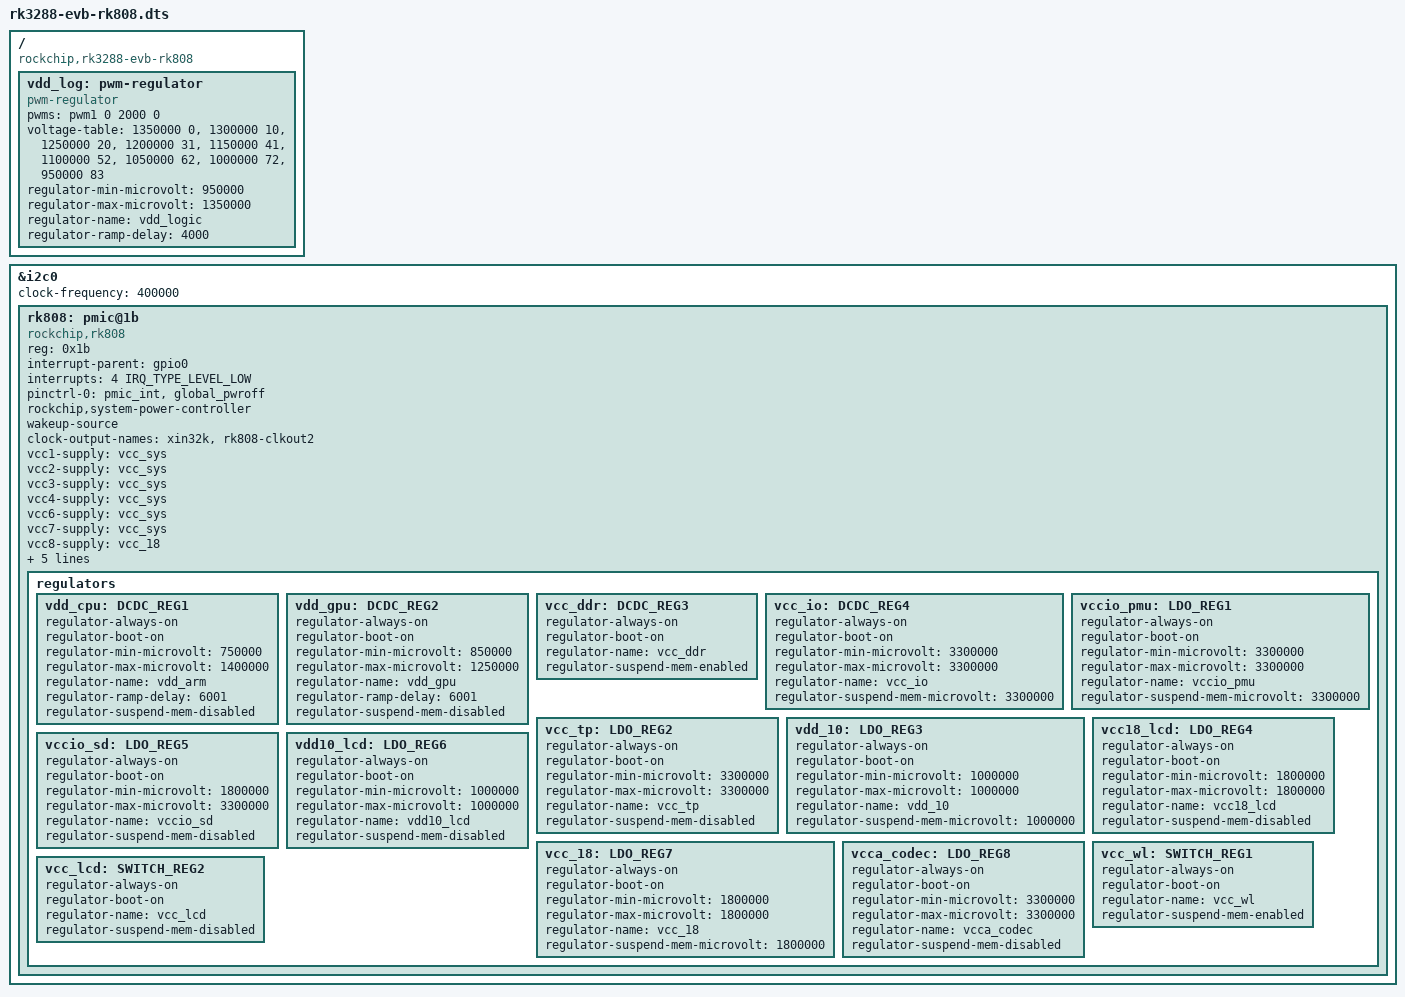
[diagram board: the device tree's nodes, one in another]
/*
 * This file is dual-licensed: you can use it either under the terms
 * of the GPL or the X11 license, at your option. Note that this dual
 * licensing only applies to this file, and not this project as a
 * whole.
 *
 *  a) This file is free software; you can redistribute it and/or
 *     modify it under the terms of the GNU General Public License as
 *     published by the Free Software Foundation; either version 2 of the
 *     License, or (at your option) any later version.
 *
 *     This file is distributed in the hope that it will be useful,
 *     but WITHOUT ANY WARRANTY; without even the implied warranty of
 *     MERCHANTABILITY or FITNESS FOR A PARTICULAR PURPOSE.  See the
 *     GNU General Public License for more details.
 *
 * Or, alternatively,
 *
 *  b) Permission is hereby granted, free of charge, to any person
 *     obtaining a copy of this software and associated documentation
 *     files (the "Software"), to deal in the Software without
 *     restriction, including without limitation the rights to use,
 *     copy, modify, merge, publish, distribute, sublicense, and/or
 *     sell copies of the Software, and to permit persons to whom the
 *     Software is furnished to do so, subject to the following
 *     conditions:
 *
 *     The above copyright notice and this permission notice shall be
 *     included in all copies or substantial portions of the Software.
 *
 *     THE SOFTWARE IS PROVIDED "AS IS", WITHOUT WARRANTY OF ANY KIND,
 *     EXPRESS OR IMPLIED, INCLUDING BUT NOT LIMITED TO THE WARRANTIES
 *     OF MERCHANTABILITY, FITNESS FOR A PARTICULAR PURPOSE AND
 *     NONINFRINGEMENT. IN NO EVENT SHALL THE AUTHORS OR COPYRIGHT
 *     HOLDERS BE LIABLE FOR ANY CLAIM, DAMAGES OR OTHER LIABILITY,
 *     WHETHER IN AN ACTION OF CONTRACT, TORT OR OTHERWISE, ARISING
 *     FROM, OUT OF OR IN CONNECTION WITH THE SOFTWARE OR THE USE OR
 *     OTHER DEALINGS IN THE SOFTWARE.
 */

/dts-v1/;
#include "rk3288-evb.dtsi"

/ {
	compatible = "rockchip,rk3288-evb-rk808", "google,veyron-jerry-rev0",
		     "rockchip,rk3288";

	vdd_log: pwm-regulator {
		compatible = "pwm-regulator";
		pwms = <&pwm1 0 2000 0>;

		voltage-table = <1350000 0>,
				<1300000 10>,
				<1250000 20>,
				<1200000 31>,
				<1150000 41>,
				<1100000 52>,
				<1050000 62>,
				<1000000 72>,
				< 950000 83>;

		regulator-min-microvolt = <950000>;
		regulator-max-microvolt = <1350000>;
		regulator-name = "vdd_logic";
		regulator-ramp-delay = <4000>;
	};
};

&i2c0 {
	clock-frequency = <400000>;

	rk808: pmic@1b {
		compatible = "rockchip,rk808";
		reg = <0x1b>;
		interrupt-parent = <&gpio0>;
		interrupts = <4 IRQ_TYPE_LEVEL_LOW>;
		pinctrl-names = "default";
		pinctrl-0 = <&pmic_int &global_pwroff>;
		rockchip,system-power-controller;
		wakeup-source;
		#clock-cells = <1>;
		clock-output-names = "xin32k", "rk808-clkout2";

		vcc1-supply = <&vcc_sys>;
		vcc2-supply = <&vcc_sys>;
		vcc3-supply = <&vcc_sys>;
		vcc4-supply = <&vcc_sys>;
		vcc6-supply = <&vcc_sys>;
		vcc7-supply = <&vcc_sys>;
		vcc8-supply = <&vcc_18>;
		vcc9-supply = <&vcc_io>;
		vcc10-supply = <&vcc_io>;
		vcc11-supply = <&vcc_sys>;
		vcc12-supply = <&vcc_io>;
		vddio-supply = <&vccio_pmu>;

		regulators {
			vdd_cpu: DCDC_REG1 {
				regulator-always-on;
				regulator-boot-on;
				regulator-min-microvolt = <750000>;
				regulator-max-microvolt = <1400000>;
				regulator-name = "vdd_arm";
				regulator-ramp-delay = <6001>;
				regulator-suspend-mem-disabled;
			};

			vdd_gpu: DCDC_REG2 {
				regulator-always-on;
				regulator-boot-on;
				regulator-min-microvolt = <850000>;
				regulator-max-microvolt = <1250000>;
				regulator-name = "vdd_gpu";
				regulator-ramp-delay = <6001>;
				regulator-suspend-mem-disabled;
			};

			vcc_ddr: DCDC_REG3 {
				regulator-always-on;
				regulator-boot-on;
				regulator-name = "vcc_ddr";
				regulator-suspend-mem-enabled;
			};

			vcc_io: DCDC_REG4 {
				regulator-always-on;
				regulator-boot-on;
				regulator-min-microvolt = <3300000>;
				regulator-max-microvolt = <3300000>;
				regulator-name = "vcc_io";
				regulator-suspend-mem-microvolt = <3300000>;
			};

			vccio_pmu: LDO_REG1 {
				regulator-always-on;
				regulator-boot-on;
				regulator-min-microvolt = <3300000>;
				regulator-max-microvolt = <3300000>;
				regulator-name = "vccio_pmu";
				regulator-suspend-mem-microvolt = <3300000>;
			};

			vcc_tp: LDO_REG2 {
				regulator-always-on;
				regulator-boot-on;
				regulator-min-microvolt = <3300000>;
				regulator-max-microvolt = <3300000>;
				regulator-name = "vcc_tp";
				regulator-suspend-mem-disabled;
			};

			vdd_10: LDO_REG3 {
				regulator-always-on;
				regulator-boot-on;
				regulator-min-microvolt = <1000000>;
				regulator-max-microvolt = <1000000>;
				regulator-name = "vdd_10";
				regulator-suspend-mem-microvolt = <1000000>;
			};

			vcc18_lcd: LDO_REG4 {
				regulator-always-on;
				regulator-boot-on;
				regulator-min-microvolt = <1800000>;
				regulator-max-microvolt = <1800000>;
				regulator-name = "vcc18_lcd";
				regulator-suspend-mem-disabled;
			};

			vccio_sd: LDO_REG5 {
				regulator-always-on;
				regulator-boot-on;
				regulator-min-microvolt = <1800000>;
				regulator-max-microvolt = <3300000>;
				regulator-name = "vccio_sd";
				regulator-suspend-mem-disabled;
			};

			vdd10_lcd: LDO_REG6 {
				regulator-always-on;
				regulator-boot-on;
				regulator-min-microvolt = <1000000>;
				regulator-max-microvolt = <1000000>;
				regulator-name = "vdd10_lcd";
				regulator-suspend-mem-disabled;
			};

			vcc_18: LDO_REG7 {
				regulator-always-on;
				regulator-boot-on;
				regulator-min-microvolt = <1800000>;
				regulator-max-microvolt = <1800000>;
				regulator-name = "vcc_18";
				regulator-suspend-mem-microvolt = <1800000>;
			};

			vcca_codec: LDO_REG8 {
				regulator-always-on;
				regulator-boot-on;
				regulator-min-microvolt = <3300000>;
				regulator-max-microvolt = <3300000>;
				regulator-name = "vcca_codec";
				regulator-suspend-mem-disabled;
			};

			vcc_wl: SWITCH_REG1 {
				regulator-always-on;
				regulator-boot-on;
				regulator-name = "vcc_wl";
				regulator-suspend-mem-enabled;
			};

			vcc_lcd: SWITCH_REG2 {
				regulator-always-on;
				regulator-boot-on;
				regulator-name = "vcc_lcd";
				regulator-suspend-mem-disabled;
			};
		};
	};
};
